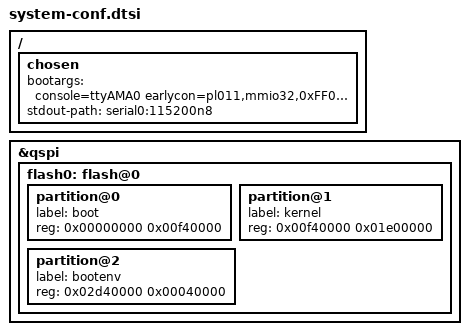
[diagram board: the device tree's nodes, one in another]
/*
 * CAUTION: This file is automatically generated by PetaLinux SDK.
 * DO NOT modify this file
 */


/ {
	chosen {
		bootargs = "console=ttyAMA0  earlycon=pl011,mmio32,0xFF000000,115200n8 clk_ignore_unused init_fatal_sh=1";
		stdout-path = "serial0:115200n8";
	};
};

&qspi {
	#address-cells = <1>;
	#size-cells = <0>;
	flash0: flash@0 {
		/delete-node/ partition@0;
		/delete-node/ partition@100000;
		/delete-node/ partition@600000;
		/delete-node/ partition@620000;
		/delete-node/ partition@c00000;
		partition@0 {
			label = "boot";
			reg = <0x00000000 0x00f40000>;
		};
		partition@1 {
			label = "kernel";
			reg = <0x00f40000 0x01e00000>;
		};
		partition@2 {
			label = "bootenv";
			reg = <0x02d40000 0x00040000>;
		};
	};
};

